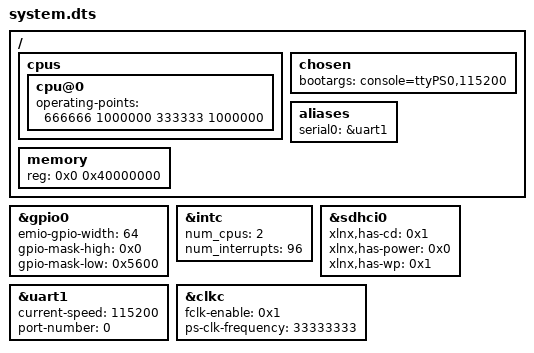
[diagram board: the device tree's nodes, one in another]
/*
 * CAUTION: This file is automatically generated by Xilinx.
 * Version:  
 * Today is: Wed May  4 16:08:56 2016
*/


/dts-v1/;
/include/ "zynq-7000.dtsi"
/include/ "pl.dtsi"
/ {
	cpus {
		cpu@0 {
			operating-points = <666666 1000000 333333 1000000>;
		};
	};
	chosen {
		bootargs = "console=ttyPS0,115200";
	};
	aliases {
		serial0 = &uart1;
	};
	memory {
		device_type = "memory";
		reg = <0x0 0x40000000>;
	};
};
&gpio0 {
	emio-gpio-width = <64>;
	gpio-mask-high = <0x0>;
	gpio-mask-low = <0x5600>;
};
&intc {
	num_cpus = <2>;
	num_interrupts = <96>;
};
&sdhci0 {
	status = "okay";
	xlnx,has-cd = <0x1>;
	xlnx,has-power = <0x0>;
	xlnx,has-wp = <0x1>;
};
&uart1 {
	current-speed = <115200>;
	device_type = "serial";
	port-number = <0>;
	status = "okay";
};
&clkc {
	fclk-enable = <0x1>;
	ps-clk-frequency = <33333333>;
};
